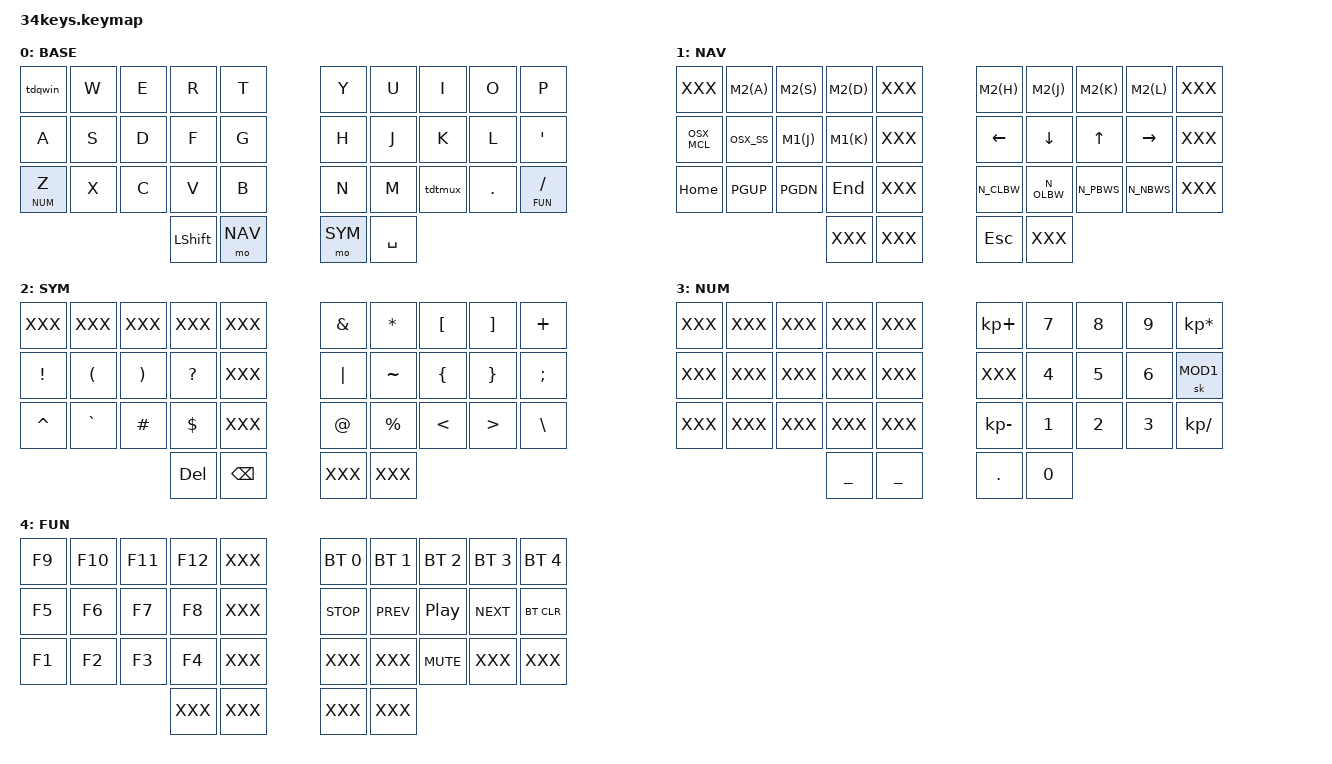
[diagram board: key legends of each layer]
#include <behaviors.dtsi>
#include <dt-bindings/zmk/keys.h>
#include <dt-bindings/zmk/bt.h>
#include "34keys.h"

&sk {
    release-after-ms = <STICKY_KEYS_TIMEOUT>;
    quick-release;
};

&caps_word {
  continue-list = <UNDERSCORE MINUS BSPC>;
};

/ {

  combos {
    #include "combos.dtsi"
  };

  behaviours {

    tdtmux: tap_dance_tmux {
      compatible = "zmk,behavior-tap-dance";
      label = "TAP_DANCE_TMUX";
      #binding-cells = <0>;
      tapping-term-ms = <200>;
      bindings = <&kp COMMA>, <&kp LC(A)>;
    };

    tdqwin: tap_dance_qwin {
      compatible = "zmk,behavior-tap-dance";
      label = "TAP_DANCE_QWIN";
      #binding-cells = <0>;
      tapping-term-ms = <250>;
      bindings = <&kp Q>, <&sk MOD1>, <&sk MOD2>;
    };

    klt: alphakey_layer_tap {
      compatible = "zmk,behavior-hold-tap";
      label = "ALPHAKEY_LAYER_TAP";
      #binding-cells = <2>;
      flavor = "balanced";
      tapping-term-ms = <150>;
      quick-tap-ms = <150>;
      global-quick-tap;
      bindings = <&mo>, <&kp>;
    };

  }; // behaviors

  keymap {
    compatible = "zmk,keymap";

    base_layer {
      label = "BASE";
      bindings = <
        // ╭─────────────┬─────────────┬─────────────┬─────────────┬─────────────╮   ╭─────────────┬─────────────┬─────────────┬─────────────┬─────────────╮
             &tdqwin       &kp W         &kp E         &kp R         &kp T             &kp Y         &kp U         &kp I         &kp O         &kp P
        // ├─────────────┼─────────────┼─────────────┼─────────────┼─────────────┤   ├─────────────┼─────────────┼─────────────┼─────────────┼─────────────┤
             &kp A         &kp S         &kp D         &kp F         &kp G             &kp H         &kp J         &kp K         &kp L         &kp APOS
        // ├─────────────┼─────────────┼─────────────┼─────────────┼─────────────┤   ├─────────────┼─────────────┼─────────────┼─────────────┼─────────────┤
             &klt NUM Z    &kp X         &kp C         &kp V         &kp B             &kp N         &kp M         &tdtmux       &kp DOT       &klt FUN FSLH
        // ╰─────────────┴─────────────┴─────────────┼─────────────┼─────────────┤   ├─────────────┼─────────────┼─────────────┴─────────────┴─────────────╯
                                                       &kp LSHIFT    &mo NAV           &mo SYM       &kp SPACE
        //                                           ╰─────────────┴─────────────╯   ╰─────────────┴─────────────╯
      >;
    }; // base_layer

    nav_layer {
      label = "NAV";
      bindings = <
        // ╭─────────────┬─────────────┬─────────────┬─────────────┬─────────────╮   ╭─────────────┬─────────────┬─────────────┬─────────────┬─────────────╮
             XXX           &kp M2(A)     &kp M2(S)     &kp M2(D)     XXX               &kp M2(H)     &kp M2(J)     &kp M2(K)     &kp M2(L)     XXX
        // ├─────────────┼─────────────┼─────────────┼─────────────┼─────────────┤   ├─────────────┼─────────────┼─────────────┼─────────────┼─────────────┤
             &kp OSX_MCL   &kp OSX_SS    &kp M1(J)     &kp M1(K)     XXX               &kp LEFT      &kp DOWN      &kp UP        &kp RIGHT     XXX
        // ├─────────────┼─────────────┼─────────────┼─────────────┼─────────────┤   ├─────────────┼─────────────┼─────────────┼─────────────┼─────────────┤
             &kp HOME      &kp PGUP      &kp PGDN      &kp END       XXX               &kp N_CLBW    &kp N_OLBW    &kp N_PBWS    &kp N_NBWS    XXX
        // ╰─────────────┴─────────────┴─────────────┼─────────────┼─────────────┤   ├─────────────┼─────────────┼─────────────┴─────────────┴─────────────╯
                                                       XXX           XXX               &kp ESC       XXX
        //                                           ╰─────────────┴─────────────╯   ╰─────────────┴─────────────╯
      >;
    }; // nav_layer

    sym_layer {
      label = "SYM";
      bindings = <
        // ╭─────────────┬─────────────┬─────────────┬─────────────┬─────────────╮   ╭─────────────┬─────────────┬─────────────┬─────────────┬─────────────╮
             XXX           XXX           XXX           XXX           XXX               &kp AMPS      &kp ASTRK     &kp LBKT      &kp RBKT      &kp PLUS
        // ├─────────────┼─────────────┼─────────────┼─────────────┼─────────────┤   ├─────────────┼─────────────┼─────────────┼─────────────┼─────────────┤
             &kp EXCL      &kp LPAR      &kp RPAR      &kp QMARK     XXX               &kp PIPE      &kp TILDE     &kp LBRC      &kp RBRC      &kp SEMI
        // ├─────────────┼─────────────┼─────────────┼─────────────┼─────────────┤   ├─────────────┼─────────────┼─────────────┼─────────────┼─────────────┤
             &kp CARET     &kp GRAVE     &kp HASH      &kp DLLR      XXX               &kp AT        &kp PRCNT     &kp LT        &kp GT        &kp BSLH
        // ╰─────────────┴─────────────┴─────────────┼─────────────┼─────────────┤   ├─────────────┼─────────────┼─────────────┴─────────────┴─────────────╯
                                                       &kp DEL       &kp BSPC          XXX           XXX
        //                                           ╰─────────────┴─────────────╯   ╰─────────────┴─────────────╯
      >;
    }; // sym_layer

    num_layer {
      label = "NUM";
      bindings = <
        // ╭─────────────┬─────────────┬─────────────┬─────────────┬─────────────╮   ╭─────────────┬─────────────┬─────────────┬─────────────┬─────────────╮
             XXX           XXX           XXX           XXX           XXX               &kp KP_PLUS   &kp N7        &kp N8        &kp N9        &kp KP_MULTIPLY
        // ├─────────────┼─────────────┼─────────────┼─────────────┼─────────────┤   ├─────────────┼─────────────┼─────────────┼─────────────┼─────────────┤
             XXX           XXX           XXX           XXX           XXX               XXX           &kp N4        &kp N5        &kp N6        &sk MOD1
        // ├─────────────┼─────────────┼─────────────┼─────────────┼─────────────┤   ├─────────────┼─────────────┼─────────────┼─────────────┼─────────────┤
             XXX           XXX           XXX           XXX           XXX               &kp KP_MINUS  &kp N1        &kp N2        &kp N3        &kp KP_DIVIDE
        // ╰─────────────┴─────────────┴─────────────┼─────────────┼─────────────┤   ├─────────────┼─────────────┼─────────────┴─────────────┴─────────────╯
                                                       ___           ___               &kp DOT       &kp N0
        //                                           ╰─────────────┴─────────────╯   ╰─────────────┴─────────────╯
      >;
    }; // num_layer

    fun_layer {
      label = "FUN";
      bindings = <
        // ╭─────────────┬─────────────┬─────────────┬─────────────┬─────────────╮   ╭─────────────┬─────────────┬─────────────┬─────────────┬─────────────╮
             &kp F9        &kp F10       &kp F11       &kp F12       XXX              &bt BT_SEL 0  &bt BT_SEL 1  &bt BT_SEL 2  &bt BT_SEL 3  &bt BT_SEL 4
        // ├─────────────┼─────────────┼─────────────┼─────────────┼─────────────┤   ├─────────────┼─────────────┼─────────────┼─────────────┼─────────────┤
             &kp F5        &kp F6        &kp F7        &kp F8        XXX               &kp C_STOP    &kp C_PREV    &kp C_PP      &kp C_NEXT    &bt BT_CLR
        // ├─────────────┼─────────────┼─────────────┼─────────────┼─────────────┤   ├─────────────┼─────────────┼─────────────┼─────────────┼─────────────┤
             &kp F1        &kp F2        &kp F3        &kp F4        XXX               XXX           XXX           &kp C_MUTE    XXX           XXX
        // ╰─────────────┴─────────────┴─────────────┼─────────────┼─────────────┤   ├─────────────┼─────────────┼─────────────┴─────────────┴─────────────╯
                                                       XXX           XXX               XXX           XXX
        //                                           ╰─────────────┴─────────────╯   ╰─────────────┴─────────────╯
      >;
    }; // fun_layer

/*
    nav_layer {
      label = "NAV";
      bindings = <
        // ╭─────────────┬─────────────┬─────────────┬─────────────┬─────────────╮   ╭─────────────┬─────────────┬─────────────┬─────────────┬─────────────╮
             XXX           XXX           XXX           XXX           XXX               XXX           XXX           XXX           XXX           XXX
        // ├─────────────┼─────────────┼─────────────┼─────────────┼─────────────┤   ├─────────────┼─────────────┼─────────────┼─────────────┼─────────────┤
             XXX           XXX           XXX           XXX           XXX               XXX           XXX           XXX           XXX           XXX
        // ├─────────────┼─────────────┼─────────────┼─────────────┼─────────────┤   ├─────────────┼─────────────┼─────────────┼─────────────┼─────────────┤
             XXX           XXX           XXX           XXX           XXX               XXX           XXX           XXX           XXX           XXX
        // ╰─────────────┴─────────────┴─────────────┼─────────────┼─────────────┤   ├─────────────┼─────────────┼─────────────┴─────────────┴─────────────╯
                                                       XXX           XXX               XXX           XXX
        //                                           ╰─────────────┴─────────────╯   ╰─────────────┴─────────────╯
      >;
    }; // nav_layer
*/

  }; // keymap


}; // final closure
